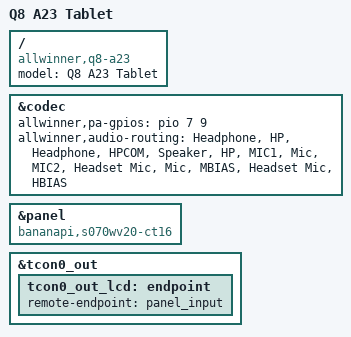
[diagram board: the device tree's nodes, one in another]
/dts-v1/;
#include "sun8i-a23.dtsi"
#include "sun8i-q8-common.dtsi"
/ {
	model = "Q8 A23 Tablet";
	compatible = "allwinner,q8-a23", "allwinner,sun8i-a23";
};
&codec {
	allwinner,pa-gpios = <&pio 7 9 GPIO_ACTIVE_HIGH>;  
	allwinner,audio-routing =
		"Headphone", "HP",
		"Headphone", "HPCOM",
		"Speaker", "HP",
		"MIC1", "Mic",
		"MIC2", "Headset Mic",
		"Mic",  "MBIAS",
		"Headset Mic", "HBIAS";
	status = "okay";
};
&panel {
	compatible = "bananapi,s070wv20-ct16";
};
&tcon0_out {
	tcon0_out_lcd: endpoint {
		remote-endpoint = <&panel_input>;
	};
};
